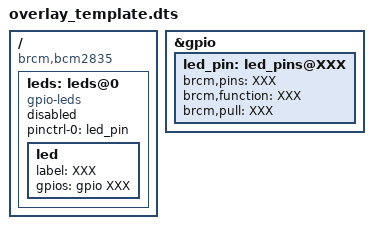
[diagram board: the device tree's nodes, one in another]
/dts-v1/;
/plugin/;

/ {
	compatible = "brcm,bcm2835";

	fragment@0 {
		// Configure the gpio pin controller
		target = <&gpio>;
		__overlay__ {
			led_pin: led_pins@XXX {  //XXX-gpio number
				brcm,pins = <XXX>; // gpio number
				brcm,function = <XXX>; // 0 = input, 1 = output
				brcm,pull = <XXX>; // 0 = none, 1 = pull down, 2 = pull up
			};
		};
	};
	fragment@1 {
		target-path = "/";
		__overlay__ {
			leds: leds@0 {
				compatible = "gpio-leds";
				pinctrl-names = "default";
				pinctrl-0 = <&led_pin>;
				status = "XXX";

				led: led {
			                label = "XXX";
					        gpios = <&gpio XXX 0>;
				};
			};
		};
	};
};
